# dsPIC33FJ64GS606 register map
Vendor: Microchip; Series: dsPIC33FJ64GS; File version: 1.4.228
Registers are 16-bit, read-write, no defined reset value unless marked. A register's access mark holds for its fields unless they carry their own. Offsets are from the block's base; [hi:lo] are bit positions; {n}, {i} and the like mark numbered series.

## PWM4 — PWM4 peripheral registers
Base 0x00000480
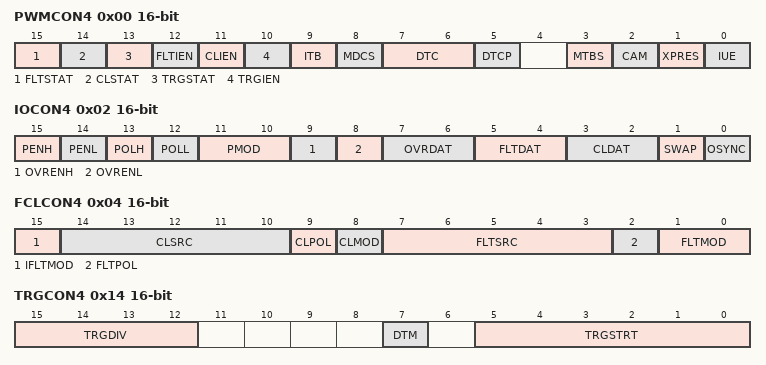
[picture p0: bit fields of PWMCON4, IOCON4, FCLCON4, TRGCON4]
0x00 PWMCON4
  [15] FLTSTAT — PWMCON4 field FLTSTAT
  [14] CLSTAT — PWMCON4 field CLSTAT
  [13] TRGSTAT — PWMCON4 field TRGSTAT
  [12] FLTIEN — PWMCON4 field FLTIEN
  [11] CLIEN — PWMCON4 field CLIEN
  [10] TRGIEN — PWMCON4 field TRGIEN
  [9] ITB — PWMCON4 field ITB
  [8] MDCS — PWMCON4 field MDCS
  [7:6] DTC — PWMCON4 field DTC
  [5] DTCP — PWMCON4 field DTCP
  [3] MTBS — PWMCON4 field MTBS
  [2] CAM — PWMCON4 field CAM
  [1] XPRES — PWMCON4 field XPRES
  [0] IUE — PWMCON4 field IUE
0x02 IOCON4
  [15] PENH — IOCON4 field PENH
  [14] PENL — IOCON4 field PENL
  [13] POLH — IOCON4 field POLH
  [12] POLL — IOCON4 field POLL
  [11:10] PMOD — IOCON4 field PMOD
  [9] OVRENH — IOCON4 field OVRENH
  [8] OVRENL — IOCON4 field OVRENL
  [7:6] OVRDAT — IOCON4 field OVRDAT
  [5:4] FLTDAT — IOCON4 field FLTDAT
  [3:2] CLDAT — IOCON4 field CLDAT
  [1] SWAP — IOCON4 field SWAP
  [0] OSYNC — IOCON4 field OSYNC
0x04 FCLCON4
  [15] IFLTMOD — FCLCON4 field IFLTMOD
  [14:10] CLSRC — FCLCON4 field CLSRC
  [9] CLPOL — FCLCON4 field CLPOL
  [8] CLMOD — FCLCON4 field CLMOD
  [7:3] FLTSRC — FCLCON4 field FLTSRC
  [2] FLTPOL — FCLCON4 field FLTPOL
  [1:0] FLTMOD — FCLCON4 field FLTMOD
0x06 PDC4
  [15:0] PDC4 — PDC4 register value
0x08 PHASE4
  [15:0] PHASE4 — PHASE4 register value
0x0A DTR4
  [13:0] DTR — DTR4 dead-time value
0x0C ALTDTR4
  [13:0] ALTDTR — ALTDTR4 dead-time value
0x0E SDC4
  [15:0] SDC4 — SDC4 register value
0x10 SPHASE4
  [15:0] SPHASE4 — SPHASE4 register value
0x12 TRIG4
  [15:3] TRGCMP — TRIG4 field TRGCMP
0x14 TRGCON4
  [15:12] TRGDIV — TRGCON4 field TRGDIV
  [7] DTM — TRGCON4 field DTM
  [5:0] TRGSTRT — TRGCON4 field TRGSTRT
0x16 STRIG4
  [15:3] STRGCMP — STRIG4 field STRGCMP
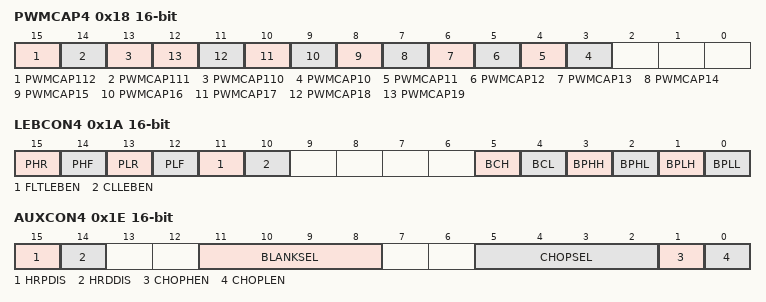
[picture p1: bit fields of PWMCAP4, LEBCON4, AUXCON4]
0x18 PWMCAP4
  [15] PWMCAP112 — PWMCAP4 field PWMCAP112
  [14] PWMCAP111 — PWMCAP4 field PWMCAP111
  [13] PWMCAP110 — PWMCAP4 field PWMCAP110
  [n-7] PWMCAP{n} (n=10..19) — PWMCAP4 field PWMCAP{n}
0x1A LEBCON4
  [15] PHR — LEBCON4 field PHR
  [14] PHF — LEBCON4 field PHF
  [13] PLR — LEBCON4 field PLR
  [12] PLF — LEBCON4 field PLF
  [11] FLTLEBEN — LEBCON4 field FLTLEBEN
  [10] CLLEBEN — LEBCON4 field CLLEBEN
  [5] BCH — LEBCON4 field BCH
  [4] BCL — LEBCON4 field BCL
  [3] BPHH — LEBCON4 field BPHH
  [2] BPHL — LEBCON4 field BPHL
  [1] BPLH — LEBCON4 field BPLH
  [0] BPLL — LEBCON4 field BPLL
0x1C LEBDLY4
  [11:3] LEB — LEBDLY4 field LEB
0x1E AUXCON4
  [15] HRPDIS — AUXCON4 field HRPDIS
  [14] HRDDIS — AUXCON4 field HRDDIS
  [11:8] BLANKSEL — AUXCON4 field BLANKSEL
  [5:2] CHOPSEL — AUXCON4 field CHOPSEL
  [1] CHOPHEN — AUXCON4 field CHOPHEN
  [0] CHOPLEN — AUXCON4 field CHOPLEN

## PWM5 — PWM5 peripheral registers
Base 0x000004A0
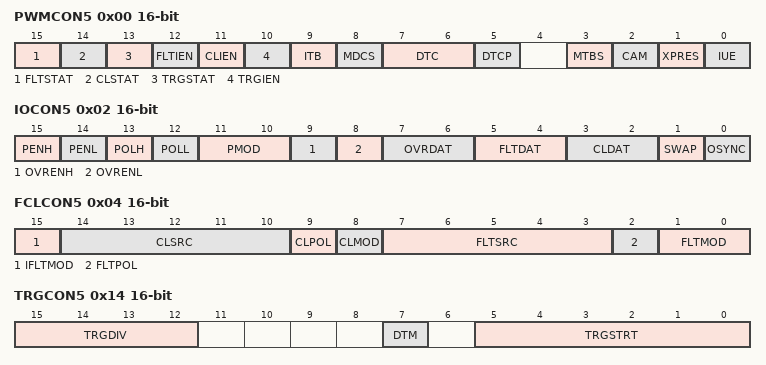
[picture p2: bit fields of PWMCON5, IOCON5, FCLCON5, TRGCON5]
0x00 PWMCON5
  [15] FLTSTAT — PWMCON5 field FLTSTAT
  [14] CLSTAT — PWMCON5 field CLSTAT
  [13] TRGSTAT — PWMCON5 field TRGSTAT
  [12] FLTIEN — PWMCON5 field FLTIEN
  [11] CLIEN — PWMCON5 field CLIEN
  [10] TRGIEN — PWMCON5 field TRGIEN
  [9] ITB — PWMCON5 field ITB
  [8] MDCS — PWMCON5 field MDCS
  [7:6] DTC — PWMCON5 field DTC
  [5] DTCP — PWMCON5 field DTCP
  [3] MTBS — PWMCON5 field MTBS
  [2] CAM — PWMCON5 field CAM
  [1] XPRES — PWMCON5 field XPRES
  [0] IUE — PWMCON5 field IUE
0x02 IOCON5
  [15] PENH — IOCON5 field PENH
  [14] PENL — IOCON5 field PENL
  [13] POLH — IOCON5 field POLH
  [12] POLL — IOCON5 field POLL
  [11:10] PMOD — IOCON5 field PMOD
  [9] OVRENH — IOCON5 field OVRENH
  [8] OVRENL — IOCON5 field OVRENL
  [7:6] OVRDAT — IOCON5 field OVRDAT
  [5:4] FLTDAT — IOCON5 field FLTDAT
  [3:2] CLDAT — IOCON5 field CLDAT
  [1] SWAP — IOCON5 field SWAP
  [0] OSYNC — IOCON5 field OSYNC
0x04 FCLCON5
  [15] IFLTMOD — FCLCON5 field IFLTMOD
  [14:10] CLSRC — FCLCON5 field CLSRC
  [9] CLPOL — FCLCON5 field CLPOL
  [8] CLMOD — FCLCON5 field CLMOD
  [7:3] FLTSRC — FCLCON5 field FLTSRC
  [2] FLTPOL — FCLCON5 field FLTPOL
  [1:0] FLTMOD — FCLCON5 field FLTMOD
0x06 PDC5
  [15:0] PDC5 — PDC5 register value
0x08 PHASE5
  [15:0] PHASE5 — PHASE5 register value
0x0A DTR5
  [13:0] DTR — DTR5 dead-time value
0x0C ALTDTR5
  [13:0] ALTDTR — ALTDTR5 dead-time value
0x0E SDC5
  [15:0] SDC5 — SDC5 register value
0x10 SPHASE5
  [15:0] SPHASE5 — SPHASE5 register value
0x12 TRIG5
  [15:3] TRGCMP — TRIG5 field TRGCMP
0x14 TRGCON5
  [15:12] TRGDIV — TRGCON5 field TRGDIV
  [7] DTM — TRGCON5 field DTM
  [5:0] TRGSTRT — TRGCON5 field TRGSTRT
0x16 STRIG5
  [15:3] STRGCMP — STRIG5 field STRGCMP
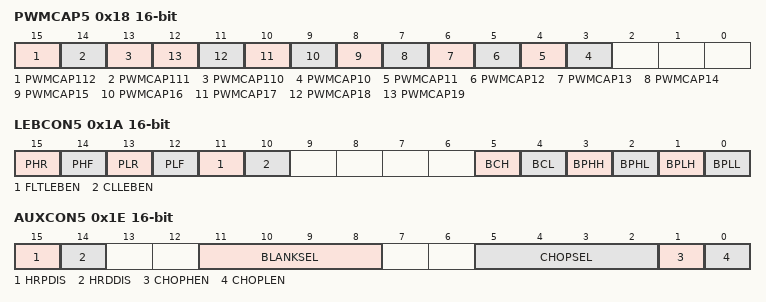
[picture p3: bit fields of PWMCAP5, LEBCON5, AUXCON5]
0x18 PWMCAP5
  [15] PWMCAP112 — PWMCAP5 field PWMCAP112
  [14] PWMCAP111 — PWMCAP5 field PWMCAP111
  [13] PWMCAP110 — PWMCAP5 field PWMCAP110
  [n-7] PWMCAP{n} (n=10..19) — PWMCAP5 field PWMCAP{n}
0x1A LEBCON5
  [15] PHR — LEBCON5 field PHR
  [14] PHF — LEBCON5 field PHF
  [13] PLR — LEBCON5 field PLR
  [12] PLF — LEBCON5 field PLF
  [11] FLTLEBEN — LEBCON5 field FLTLEBEN
  [10] CLLEBEN — LEBCON5 field CLLEBEN
  [5] BCH — LEBCON5 field BCH
  [4] BCL — LEBCON5 field BCL
  [3] BPHH — LEBCON5 field BPHH
  [2] BPHL — LEBCON5 field BPHL
  [1] BPLH — LEBCON5 field BPLH
  [0] BPLL — LEBCON5 field BPLL
0x1C LEBDLY5
  [11:3] LEB — LEBDLY5 field LEB
0x1E AUXCON5
  [15] HRPDIS — AUXCON5 field HRPDIS
  [14] HRDDIS — AUXCON5 field HRDDIS
  [11:8] BLANKSEL — AUXCON5 field BLANKSEL
  [5:2] CHOPSEL — AUXCON5 field CHOPSEL
  [1] CHOPHEN — AUXCON5 field CHOPHEN
  [0] CHOPLEN — AUXCON5 field CHOPLEN
